# TC80_VXX register map
Vendor: Geneal MCU Ltd.; Series: ARMCM0; File version: 1.2
CPU: CM0 r0p0, little endian, no MPU, no FPU, 2 interrupt priority bits
Registers are 32-bit, read-write, reset 0x0 unless marked. A register's access mark holds for its fields unless they carry their own. Offsets are from the block's base; [hi:lo] are bit positions; {n}, {i} and the like mark numbered series; 'fields as' and 'values as' point back to an identical list.

## SCU — System configuration unit
Base 0x40001000
0x00 PKR (reset mask 0xFFFF) — Protect key register
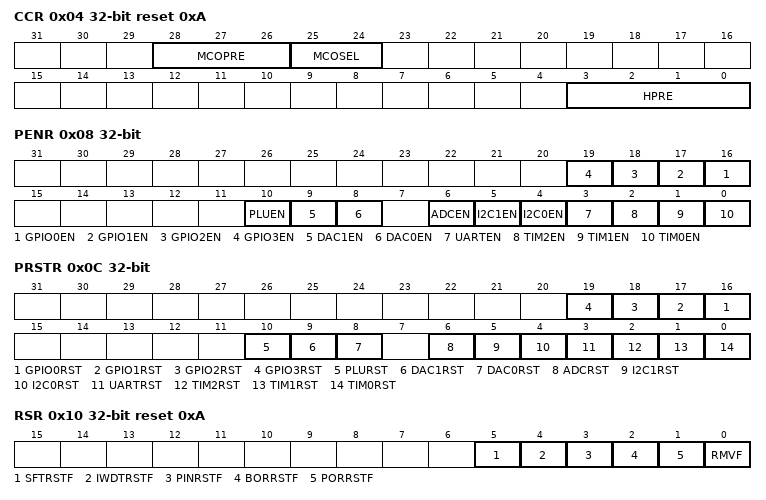
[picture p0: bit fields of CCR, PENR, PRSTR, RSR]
0x04 CCR reset 0xA (reset mask 0x300000F) — Clock configure register
  [28:26] MCOPRE — MCO prescaler
    0=Div1 (Divider by 1); 1=Div2 (Divider by 2); 2=Div4 (Divider by 4); 3=Div8 (Divider by 8); 4=Div16 (Divider by 16); 5=Div32 (Divider by 32)
  [25:24] MCOSEL — Micro clock output select
    0=Disable (MCO output disabled); 1=HRC (HRC select); 2=LRC (LRC select)
  [3:0] HPRE — HCLK prescaler
    0=Div1 (Divider by 1); 8=Div2 (Divider by 2); 9=Div4 (Divider by 4); 10=Div8 (Divider by 8); 11=Div16 (Divider by 16); 12=Div32 (Divider by 32); 13=Div64 (Divider by 64); 14=Div128 (Divider by 128); 15=Div256 (Divider by 256)
0x08 PENR (reset mask 0xF3F) — Peripheral clock enable register
  [n+16] GPIO{n}EN (n=0..3) — GPIO {n} clock enable
    0=Disable (GPIO {n} clock disabled); 1=Enable (GPIO {n} clock enabled)
  [10] PLUEN — PLUEN clock enable
    0=Disable (PLU clock disabled); 1=Enable (PLU clock enabled)
  [9] DAC1EN — DAC0 clock enable
    0=Disable (DAC1 clock disabled); 1=Enable (DAC1 clock enabled)
  [8] DAC0EN — DAC0 clock enable
    0=Disable (DAC0 clock disabled); 1=Enable (DAC0 clock enabled)
  [6] ADCEN — ADC clock enable
    0=Disable (ADC clock disabled); 1=Enable (ADC clock enabled)
  [5] I2C1EN — I2C1 clock enable
    0=Disable (I2C1 clock disabled); 1=Enable (I2C1 clock enabled)
  [4] I2C0EN — I2C0 clock enable
    0=Disable (I2C0 clock disabled); 1=Enable (I2C0 clock enabled)
  [3] UARTEN — UART clock enable
    0=Disable (UART clock disabled); 1=Enable (UART clock enabled)
  [2] TIM2EN — timer 2 clock enable
    0=Disable (Timer 2 clock disabled); 1=Enable (Timer 2 clock enabled)
  [1] TIM1EN — timer 1 clock enable
    0=Disable (Timer 1 clock disabled); 1=Enable (Timer 1 clock enabled)
  [0] TIM0EN — timer 0 clock enable
    0=Disable (Timer 0 clock disabled); 1=Enable (Timer 0 clock enabled)
0x0C PRSTR (reset mask 0xF3F) — Peripheral reset register
  [n+16] GPIO{n}RST (n=0..3) — Reset GPIO {n}
    0=No_Action; 1=Reset GPIO {n}
  [10] PLURST — Reset PLU
    0=No_Action; 1=Reset PLU
  [9] DAC1RST — Reset DAC1
    0=No_Action; 1=Reset DAC1
  [8] DAC0RST — Reset DAC0
    0=No_Action; 1=Reset DAC0
  [6] ADCRST — Reset ADC
    0=No_Action; 1=Reset ADC
  [5] I2C1RST — Reset I2C1
    0=No_Action; 1=Reset I2C1
  [4] I2C0RST — Reset I2C0
    0=No_Action; 1=Reset I2C0
  [3] UARTRST — Reset UART
    0=No_Action; 1=Reset UART
  [2] TIM2RST — Reset Timer 2
    0=No_Action; 1=Reset timer 2
  [1] TIM1RST — Reset Timer 1
    0=No_Action; 1=Reset timer 1
  [0] TIM0RST — Reset Timer 0
    0=No_Action; 1=Reset timer 0
0x10 RSR reset 0xA — Reset status register
  [5] SFTRSTF ro — Soft reset flags
  [4] IWDTRSTF ro — IWDT reset flags
  [3] PINRSTF ro — PIN reset flags
  [2] BORRSTF ro — BOR reset flags
  [1] PORRSTF ro — POR reset flags
  [0] RMVF — Remove reset flags
    0=No_Action; 1=Remove_Flag (Remove all reset flags)
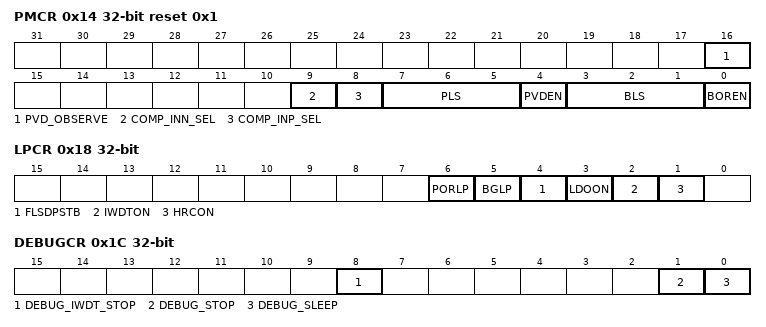
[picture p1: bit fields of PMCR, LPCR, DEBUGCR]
0x14 PMCR reset 0x1 (reset mask 0xFF) — Power monitor config register
  [16] PVD_OBSERVE ro — PVD value Observe bit
  [9] COMP_INN_SEL — COMP Neg INPUT select
    0=Disable (COMP Neg select internal Resistence); 1=Enable (COMP Neg select PAD)
  [8] COMP_INP_SEL — COMP Pos INPUT select
    0=Disable (COMP Pos select internal Resistence); 1=Enable (COMP Pos select PAD)
  [7:5] PLS — PVD level select
    0=1P8 (1.80 V); 1=2P0 (2.0 V); 2=2P25 (2.25 V); 3=2P5 (2.5 V); 4=2P75 (2.75 V); 5=3P0 (3.0 V); 6=3P6 (3.6 V); 7=4P0 (4.0 V)
  [4] PVDEN — PVD enable
    0=Disable (PVD is disabled); 1=Enable (PVD is enabled)
  [3:1] BLS — BOR level select
    values as PLS
  [0] BOREN — BOR enable
    0=Disable (BOR is disabled); 1=Enable (BOR is enabled)
0x18 LPCR — Low power mode config register
  [6] PORLP — POR module low power mode enable
    0=Disable (POR module low power mode disable); 1=Enable (POR module low power mode enable)
  [5] BGLP — Bandgap low power mode enable
    0=Disable (Bandgap low power mode disable); 1=Enable (Bandgap low power mode enable)
  [4] FLSDPSTB — Flash deep standby mode when stop mode
    0=Disable (Flash not deep standby mode when stop mode); 1=Enable (Flash deep standby mode when stop mode)
  [3] LDOON — LDO normal mode when stop mode
    0=Disable (LDO low power mode when stop mode); 1=Enable (LDO normal mode when stop mode)
  [2] IWDTON — HRC not stoped when stop mode
    0=Disable (WDT stoped when sleep/stop mode); 1=Enable (WDT not stoped when sleep/stop mode)
  [1] HRCON — HRC not stoped when stop mode
    0=Disable (HRC stoped when stop mode); 1=Enable (HRC not stoped when stop mode)
0x1C DEBUGCR (reset mask 0x13) — debug mode config Register
  [8] DEBUG_IWDT_STOP — Config IWDT at stop mode
  [1] DEBUG_STOP — Config FCLK HCLK at stop mode
  [0] DEBUG_SLEEP — Config FCLK HCLK at sleep mode
0x20 STR reset 0x3A97F (reset mask 0xFFFF) — Systick calibration register
  [23:0] TENMS — Calibration value for 10ms
0x24 BSR — Memory mapping selection register
  [0] BOOT — Boot select
    0=FLASH (Boot from FLASH); 1=SRAM (Boot from SRAM)
